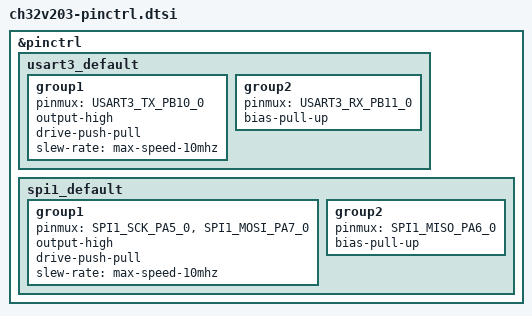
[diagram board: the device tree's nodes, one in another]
/*
 * Copyright (c) 2026 Fiona Behrens
 * SPDX-License-Identifier: Apache-2.0
 */

#include <zephyr/dt-bindings/pinctrl/ch32v20x_30x-pinctrl.h>

&pinctrl {
	usart3_default: usart3_default {
		group1 {
			pinmux = <USART3_TX_PB10_0>;
			output-high;
			drive-push-pull;
			slew-rate = "max-speed-10mhz";
		};

		group2 {
			pinmux = <USART3_RX_PB11_0>;
			bias-pull-up;
		};
	};

	/omit-if-no-ref/ spi1_default: spi1_default {
		group1 {
			pinmux = <SPI1_SCK_PA5_0>, <SPI1_MOSI_PA7_0>;
			output-high;
			drive-push-pull;
			slew-rate = "max-speed-10mhz";
		};

		group2 {
			pinmux = <SPI1_MISO_PA6_0>;
			bias-pull-up;
		};
	};
};
